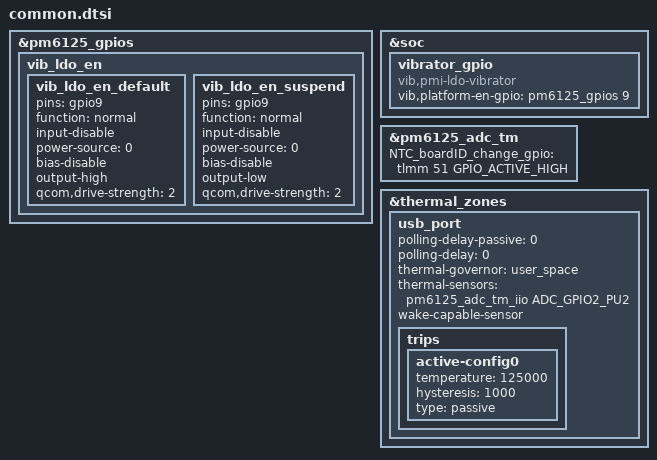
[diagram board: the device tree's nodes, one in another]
#include "../../common/common.dtsi"
#include "huawei-lcd.dtsi"
#include "huawei-tp.dtsi"
#include "huawei_audio.dtsi"
#include "huawei-sensor.dtsi"
#include "huawei_fac.dtsi"
#include "huawei_charger_xxw.dtsi"
#include "huawei_bt.dtsi"
#include "huawei_fp.dtsi"

&pm6125_gpios {
    vib_ldo_en {
        vib_ldo_en_default:vib_ldo_en_default {
            pins = "gpio9";
            function = "normal";
            input-disable;
            power-source = <0>;
            bias-disable;
            output-high;
            qcom,drive-strength = <2>;
        };
        vib_ldo_en_suspend:vib_ldo_en_suspend {
            pins = "gpio9";
            function = "normal";
            input-disable;
            power-source = <0>;
            bias-disable;
            output-low;
            qcom,drive-strength = <2>;
        };
    };
};

&soc {
    vibrator_gpio {
        compatible = "vib,pmi-ldo-vibrator";
        vib,platform-en-gpio = <&pm6125_gpios 9 GPIO_ACTIVE_HIGH>;
    };
};

&pm6125_adc_tm {
	NTC_boardID_change_gpio = <&tlmm 51 GPIO_ACTIVE_HIGH>;
};

&thermal_zones {
	usb_port {
		polling-delay-passive = <0>;
		polling-delay = <0>;
		thermal-governor = "user_space";
		thermal-sensors = <&pm6125_adc_tm_iio ADC_GPIO2_PU2>;
		wake-capable-sensor;
		trips {
			active-config0 {
				temperature = <125000>;
				hysteresis = <1000>;
				type = "passive";
			};
		};
	};
};
